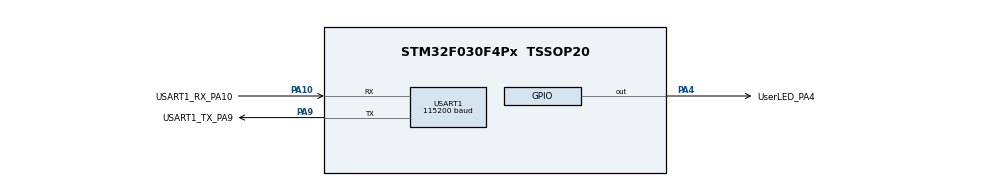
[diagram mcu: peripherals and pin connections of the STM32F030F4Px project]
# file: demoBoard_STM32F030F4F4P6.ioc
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Mcu.Family=STM32F0
Mcu.Name=STM32F030F4Px
Mcu.Package=TSSOP20
NVIC.USART1_IRQn=true\:0\:0\:false\:false\:true\:true\:true
PA10.GPIO_Label=USART1_RX_PA10
PA10.Mode=Asynchronous
PA10.Signal=USART1_RX
PA13.GPIO_Label=SYS_SWDIO_PA13
PA13.Mode=Serial_Wire
PA13.Signal=SYS_SWDIO
PA14.GPIO_Label=SYS_SWCLK_PA14
PA14.Mode=Serial_Wire
PA14.Signal=SYS_SWCLK
PA4.GPIO_Label=UserLED_PA4
PA4.Signal=GPIO_Output
PA9.GPIO_Label=USART1_TX_PA9
PA9.Mode=Asynchronous
PA9.Signal=USART1_TX
PF0-OSC_IN.Mode=HSE-External-Oscillator
PF0-OSC_IN.Signal=RCC_OSC_IN
PF1-OSC_OUT.Mode=HSE-External-Oscillator
PF1-OSC_OUT.Signal=RCC_OSC_OUT
ProjectManager.HeapSize=0x200
ProjectManager.StackSize=0x400
ProjectManager.TargetToolchain=MDK-ARM V5.27
RCC.AHBFreq_Value=48000000
RCC.APB1Freq_Value=48000000
RCC.APB1TimFreq_Value=48000000
RCC.HCLKFreq_Value=48000000
RCC.PLLMUL=RCC_PLL_MUL6
RCC.PLLSourceVirtual=RCC_PLLSOURCE_HSE
RCC.SYSCLKFreq_VALUE=48000000
RCC.SYSCLKSource=RCC_SYSCLKSOURCE_PLLCLK
USART1.BaudRate=115200
USART1.VirtualMode-Asynchronous=VM_ASYNC
board=custom

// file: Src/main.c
/* USER CODE BEGIN Header */
/**
  ******************************************************************************
  * @file           : main.c
  * @brief          : Main program body
  ******************************************************************************
  * @attention
  *
  * <h2><center>&copy; Copyright (c) 2020 STMicroelectronics.
  * All rights reserved.</center></h2>
  *
  * This software component is licensed by ST under BSD 3-Clause license,
  * the "License"; You may not use this file except in compliance with the
  * License. You may obtain a copy of the License at:
  *                        opensource.org/licenses/BSD-3-Clause
  *
  ******************************************************************************
  */
/* USER CODE END Header */

#include "main.h"

/* USER CODE BEGIN Includes */
#include "trice.h"
/* USER CODE END Includes */

void SystemClock_Config(void);
static void MX_GPIO_Init(void);
static void MX_USART1_UART_Init(void);

int main(void)
{
  /* USER CODE BEGIN 1 */
#ifdef ENCRYPT
    InitXteaTable();
#endif
  /* USER CODE END 1 */

  /* MCU Configuration--------------------------------------------------------*/

  /* Reset of all peripherals, Initializes the Flash interface and the Systick. */

  LL_APB1_GRP2_EnableClock(LL_APB1_GRP2_PERIPH_SYSCFG);
  LL_APB1_GRP1_EnableClock(LL_APB1_GRP1_PERIPH_PWR);

  /* System interrupt init*/

  /* Configure the system clock */
  SystemClock_Config();

  /* USER CODE BEGIN SysInit */
    SysTick->CTRL |= SysTick_CTRL_TICKINT_Msk; // enable SysTick interrupt
  /* USER CODE END SysInit */

  /* Initialize all configured peripherals */
  MX_GPIO_Init();
  MX_USART1_UART_Init();
  /* USER CODE BEGIN 2 */
    LL_USART_EnableIT_RXNE(USART1); // enable UART1 interrupt
  /* USER CODE END 2 */

  /* Infinite loop */
  /* USER CODE BEGIN WHILE */
    TRICE16_1( Id( 2625), "TIM:timing      message, SysTick is %6d\n", SYSTICKVAL16 );
    TRICE0( Id( 3173), "att:demoBoard_STM32F030F4F4P6\n" );
    TRICE16_1( Id( 2625), "TIM:timing      message, SysTick is %6d\n", SYSTICKVAL16 );
    TRICE16_1( Id( 2625), "TIM:timing      message, SysTick is %6d\n", SYSTICKVAL16 );
    TRICE16_1( Id( 2625), "TIM:timing      message, SysTick is %6d\n", SYSTICKVAL16 );
    TRICE16_1( Id( 2625), "TIM:timing      message, SysTick is %6d\n", SYSTICKVAL16 );
    while (1)
    {
      //////////////////////////////////////////////////
      // demo trices
      //
      static uint32_t ms_1 = 0;
      if( ms >= ms_1 + 300 ){ // every 300 ms
          TRICE32_1( Id(29200), "time:ms = %d\n", ms );
          ms_1 = ms;
      }
      //
      //////////////////////////////////////////////////

      //////////////////////////////////////////////////
      // needed background activity
      //
        #ifdef LL_INTERFACE_NO_INTERRUPTS
        triceServe();
        #endif
      //
      //////////////////////////////////////////////////
    /* USER CODE END WHILE */

  }
}

void SystemClock_Config(void)
{
  LL_FLASH_SetLatency(LL_FLASH_LATENCY_1);

  if(LL_FLASH_GetLatency() != LL_FLASH_LATENCY_1)
  {
  Error_Handler();
  }
  LL_RCC_HSE_Enable();

   /* Wait till HSE is ready */
  while(LL_RCC_HSE_IsReady() != 1)
  {

  }
  LL_RCC_PLL_ConfigDomain_SYS(LL_RCC_PLLSOURCE_HSE_DIV_1, LL_RCC_PLL_MUL_6);
  LL_RCC_PLL_Enable();

   /* Wait till PLL is ready */
  while(LL_RCC_PLL_IsReady() != 1)
  {

  }
  LL_RCC_SetAHBPrescaler(LL_RCC_SYSCLK_DIV_1);
  LL_RCC_SetAPB1Prescaler(LL_RCC_APB1_DIV_1);
  LL_RCC_SetSysClkSource(LL_RCC_SYS_CLKSOURCE_PLL);

   /* Wait till System clock is ready */
  while(LL_RCC_GetSysClkSource() != LL_RCC_SYS_CLKSOURCE_STATUS_PLL)
  {

  }
  LL_Init1msTick(48000000);
  LL_SetSystemCoreClock(48000000);
  LL_RCC_SetUSARTClockSource(LL_RCC_USART1_CLKSOURCE_PCLK1);
}

static void MX_USART1_UART_Init(void)
{

  LL_USART_InitTypeDef USART_InitStruct = {0};

  LL_GPIO_InitTypeDef GPIO_InitStruct = {0};

  /* Peripheral clock enable */
  LL_APB1_GRP2_EnableClock(LL_APB1_GRP2_PERIPH_USART1);

  LL_AHB1_GRP1_EnableClock(LL_AHB1_GRP1_PERIPH_GPIOA);
  /**USART1 GPIO Configuration
  PA9   ------> USART1_TX
  PA10   ------> USART1_RX
  */
  GPIO_InitStruct.Pin = USART1_TX_PA9_Pin;
  GPIO_InitStruct.Mode = LL_GPIO_MODE_ALTERNATE;
  GPIO_InitStruct.Speed = LL_GPIO_SPEED_FREQ_HIGH;
  GPIO_InitStruct.OutputType = LL_GPIO_OUTPUT_PUSHPULL;
  GPIO_InitStruct.Pull = LL_GPIO_PULL_NO;
  GPIO_InitStruct.Alternate = LL_GPIO_AF_1;
  LL_GPIO_Init(USART1_TX_PA9_GPIO_Port, &GPIO_InitStruct);

  GPIO_InitStruct.Pin = USART1_RX_PA10_Pin;
  GPIO_InitStruct.Mode = LL_GPIO_MODE_ALTERNATE;
  GPIO_InitStruct.Speed = LL_GPIO_SPEED_FREQ_HIGH;
  GPIO_InitStruct.OutputType = LL_GPIO_OUTPUT_PUSHPULL;
  GPIO_InitStruct.Pull = LL_GPIO_PULL_NO;
  GPIO_InitStruct.Alternate = LL_GPIO_AF_1;
  LL_GPIO_Init(USART1_RX_PA10_GPIO_Port, &GPIO_InitStruct);

  /* USART1 interrupt Init */
  NVIC_SetPriority(USART1_IRQn, 0);
  NVIC_EnableIRQ(USART1_IRQn);

  USART_InitStruct.BaudRate = 115200;
  USART_InitStruct.DataWidth = LL_USART_DATAWIDTH_8B;
  USART_InitStruct.StopBits = LL_USART_STOPBITS_1;
  USART_InitStruct.Parity = LL_USART_PARITY_NONE;
  USART_InitStruct.TransferDirection = LL_USART_DIRECTION_TX_RX;
  USART_InitStruct.HardwareFlowControl = LL_USART_HWCONTROL_NONE;
  USART_InitStruct.OverSampling = LL_USART_OVERSAMPLING_16;
  LL_USART_Init(USART1, &USART_InitStruct);
  LL_USART_DisableIT_CTS(USART1);
  LL_USART_ConfigAsyncMode(USART1);
  LL_USART_Enable(USART1);

}

static void MX_GPIO_Init(void)
{
  LL_GPIO_InitTypeDef GPIO_InitStruct = {0};

  /* GPIO Ports Clock Enable */
  LL_AHB1_GRP1_EnableClock(LL_AHB1_GRP1_PERIPH_GPIOF);
  LL_AHB1_GRP1_EnableClock(LL_AHB1_GRP1_PERIPH_GPIOA);

  /**/
  LL_GPIO_ResetOutputPin(UserLED_PA4_GPIO_Port, UserLED_PA4_Pin);

  /**/
  GPIO_InitStruct.Pin = UserLED_PA4_Pin;
  GPIO_InitStruct.Mode = LL_GPIO_MODE_OUTPUT;
  GPIO_InitStruct.Speed = LL_GPIO_SPEED_FREQ_LOW;
  GPIO_InitStruct.OutputType = LL_GPIO_OUTPUT_PUSHPULL;
  GPIO_InitStruct.Pull = LL_GPIO_PULL_NO;
  LL_GPIO_Init(UserLED_PA4_GPIO_Port, &GPIO_InitStruct);

}

void Error_Handler(void)
{
}

/************************ (C) COPYRIGHT STMicroelectronics *****END OF FILE****/
